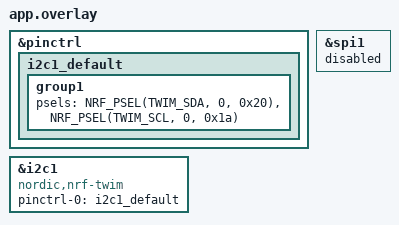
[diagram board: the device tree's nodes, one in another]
&pinctrl {
	i2c1_default: i2c1_default {
		group1 {
			psels = <NRF_PSEL(TWIM_SDA, 0, 0x20)>,
				<NRF_PSEL(TWIM_SCL, 0, 0x1a)>;
		};
	};
};

&spi1 {
    status = "disabled";
};

&i2c1 {
	compatible = "nordic,nrf-twim";
	status = "okay";
	pinctrl-0 = <&i2c1_default>;
	pinctrl-names = "default";
};
